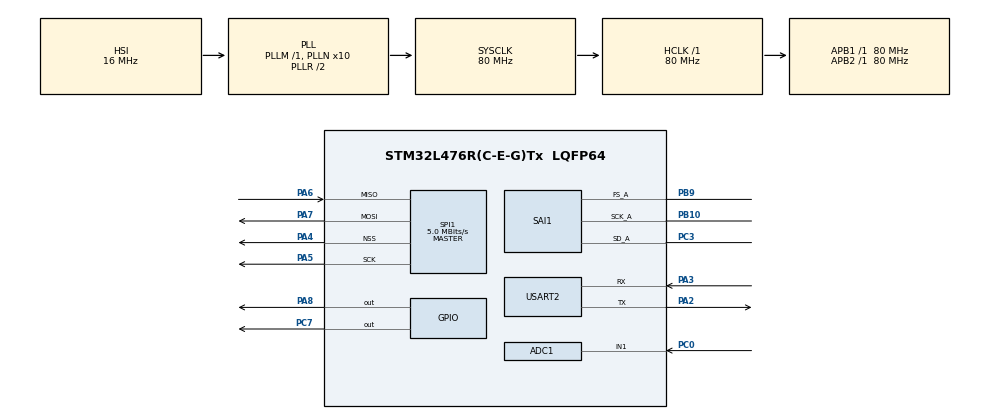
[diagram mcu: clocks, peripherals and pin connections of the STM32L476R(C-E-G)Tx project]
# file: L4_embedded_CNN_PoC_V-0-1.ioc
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ADC1.Channel-3\#ChannelRegularConversion=ADC_CHANNEL_1
ADC1.ClockPrescaler=ADC_CLOCK_ASYNC_DIV16
ADC1.NbrOfConversionFlag=1
ADC1.OffsetNumber-3\#ChannelRegularConversion=ADC_OFFSET_NONE
ADC1.Rank-3\#ChannelRegularConversion=1
ADC1.SamplingTime-3\#ChannelRegularConversion=ADC_SAMPLETIME_2CYCLES_5
ADC1.master=1
Dma.Request0=SAI1_A
Dma.SAI1_A.0.Direction=DMA_PERIPH_TO_MEMORY
Dma.SAI1_A.0.Instance=DMA2_Channel1
Dma.SAI1_A.0.MemDataAlignment=DMA_MDATAALIGN_WORD
Dma.SAI1_A.0.MemInc=DMA_MINC_ENABLE
Dma.SAI1_A.0.Mode=DMA_CIRCULAR
Dma.SAI1_A.0.PeriphDataAlignment=DMA_PDATAALIGN_WORD
Dma.SAI1_A.0.PeriphInc=DMA_PINC_DISABLE
Dma.SAI1_A.0.Priority=DMA_PRIORITY_HIGH
FREERTOS.Events01=hI2s_Evt,Dynamic,NULL
FREERTOS.Tasks01=defaultTask,24,128,StartDefaultTask,Default,NULL,Dynamic,NULL,NULL
FREERTOS.configUSE_NEWLIB_REENTRANT=1
Mcu.Family=STM32L4
Mcu.Name=STM32L476R(C-E-G)Tx
Mcu.Package=LQFP64
NVIC.DMA2_Channel1_IRQn=true\:5\:0\:false\:false\:true\:true\:false\:true
NVIC.PriorityGroup=NVIC_PRIORITYGROUP_4
NVIC.TIM1_TRG_COM_TIM17_IRQn=true\:15\:0\:false\:false\:true\:false\:false\:true
NVIC.TimeBase=TIM1_TRG_COM_TIM17_IRQn
NVIC.TimeBaseIP=TIM17
NVIC.USART2_IRQn=true\:5\:0\:false\:false\:true\:true\:true\:true
PA2.Mode=Asynchronous
PA2.Signal=USART2_TX
PA3.Mode=Asynchronous
PA3.Signal=USART2_RX
PA4.Mode=NSS_Signal_Hard_Output
PA4.Signal=SPI1_NSS
PA5.Mode=Full_Duplex_Master
PA5.Signal=SPI1_SCK
PA6.Mode=Full_Duplex_Master
PA6.Signal=SPI1_MISO
PA7.Mode=Full_Duplex_Master
PA7.Signal=SPI1_MOSI
PA8.GPIO_Speed=GPIO_SPEED_FREQ_HIGH
PA8.Signal=GPIO_Output
PB10.Mode=SAI_A_Master
PB10.Signal=SAI1_SCK_A
PB9.Mode=SAI_A_Master
PB9.Signal=SAI1_FS_A
PC0.Signal=ADCx_IN1
PC3.Mode=SAI_A_Master
PC3.Signal=SAI1_SD_A
PC7.GPIO_Speed=GPIO_SPEED_FREQ_HIGH
PC7.Signal=GPIO_Output
ProjectManager.HeapSize=0x800
ProjectManager.StackSize=0x800
ProjectManager.TargetToolchain=STM32CubeIDE
RCC.ADCFreq_Value=64000000
RCC.AHBFreq_Value=80000000
RCC.APB1Freq_Value=80000000
RCC.APB1TimFreq_Value=80000000
RCC.APB2Freq_Value=80000000
RCC.APB2TimFreq_Value=80000000
RCC.CortexFreq_Value=80000000
RCC.HCLKFreq_Value=80000000
RCC.HSE_VALUE=8000000
RCC.HSI_VALUE=16000000
RCC.LSE_VALUE=32768
RCC.MSI_VALUE=4000000
RCC.PLLN=10
RCC.PLLSourceVirtual=RCC_PLLSOURCE_HSI
RCC.PREFETCH_ENABLE=1
RCC.SYSCLKFreq_VALUE=80000000
RCC.SYSCLKSource=RCC_SYSCLKSOURCE_PLLCLK
RCC.USBFreq_Value=64000000
RCC.VCOOutputFreq_Value=160000000
SAI1.AudioFrequency-SAI_A_Master=SAI_AUDIO_FREQUENCY_48K
SAI1.AudioMode-SAI_A_Master=SAI_MODEMASTER_RX
SAI1.BasicDataSize-SAI_A_Master=SAI_PROTOCOL_DATASIZE_24BIT
SAI1.BasicProtocol-SAI_A_Master=SAI_I2S_STANDARD
SAI1.CompandingMode-SAI_A_Master=SAI_NOCOMPANDING
SAI1.ErrorAudioFreq-SAI_A_Master=48.8 %
SAI1.InitProtocol-SAI_A_Master=Enable
SAI1.Instance-SAI_A_Master=SAI$Index_Block_A
SAI1.MClockEnable-SAI_A_Master=SAI_MASTERCLOCK_DISABLE
SAI1.MonoStereoMode-SAI_A_Master=SAI_MONOMODE
SAI1.RealAudioFreq-SAI_A_Master=71.428 KHz
SAI1.VirtualMode-SAI_A_Master=VM_MASTER
SAI1.VirtualProtocol-SAI_A_BASIC=VM_BASIC_PROTOCOL
SH.ADCx_IN1.0=ADC1_IN1,IN1-Single-Ended
SPI1.BaudRatePrescaler=SPI_BAUDRATEPRESCALER_16
SPI1.CalculateBaudRate=5.0 MBits/s
SPI1.DataSize=SPI_DATASIZE_8BIT
SPI1.Direction=SPI_DIRECTION_2LINES
SPI1.Mode=SPI_MODE_MASTER
SPI1.VirtualNSS=VM_NSSHARD
SPI1.VirtualType=VM_MASTER
STMicroelectronics.X-CUBE-AI.7.1.0.ActivationBufferSizeList=46300
STMicroelectronics.X-CUBE-AI.7.1.0.ActivationBuffers=pool0
STMicroelectronics.X-CUBE-AI.7.1.0.ActivationNames=pool0
STMicroelectronics.X-CUBE-AI.7.1.0.ActivationSizes=AI_NETWORK_DATA_ACTIVATION_1_SIZE
STMicroelectronics.X-CUBE-AI.7.1.0.HeapSize=0x800
STMicroelectronics.X-CUBE-AI.7.1.0.InternalRamActivationBufferMaxSize=AI_NETWORK_DATA_ACTIVATIONS_SIZE
STMicroelectronics.X-CUBE-AI.7.1.0.LatestDirectoryUsed-8756bf45d95c8d5ad4c280e6ead7ad80c2c09bfcceebf7f6c182002fefabbdc1=C\:\\Users\\j.tschavoll\\OneDrive - FH Vorarlberg\\Partnerunternehmen FHV\\FH\\BA\\Code\\Jupyter\\N4CED_V-0-2
STMicroelectronics.X-CUBE-AI.7.1.0.MaximumNumberOfInputLayer=1
STMicroelectronics.X-CUBE-AI.7.1.0.MaximumNumberOfOutputLayer=1
STMicroelectronics.X-CUBE-AI.7.1.0.MaximumSizeOfInputLayer=AI_NETWORK_IN_1_SIZE_BYTES
STMicroelectronics.X-CUBE-AI.7.1.0.MaximumSizeOfOutputLayer=AI_NETWORK_OUT_1_SIZE_BYTES
STMicroelectronics.X-CUBE-AI.7.1.0.ModelActualCompression-8756bf45d95c8d5ad4c280e6ead7ad80c2c09bfcceebf7f6c182002fefabbdc1=2.67
STMicroelectronics.X-CUBE-AI.7.1.0.ModelCompression-8756bf45d95c8d5ad4c280e6ead7ad80c2c09bfcceebf7f6c182002fefabbdc1=4
STMicroelectronics.X-CUBE-AI.7.1.0.ModelFlashOccupation-8756bf45d95c8d5ad4c280e6ead7ad80c2c09bfcceebf7f6c182002fefabbdc1=282460
STMicroelectronics.X-CUBE-AI.7.1.0.ModelHashList=8756bf45d95c8d5ad4c280e6ead7ad80c2c09bfcceebf7f6c182002fefabbdc1
STMicroelectronics.X-CUBE-AI.7.1.0.ModelKind-8756bf45d95c8d5ad4c280e6ead7ad80c2c09bfcceebf7f6c182002fefabbdc1=TFLITE
STMicroelectronics.X-CUBE-AI.7.1.0.ModelMacc-8756bf45d95c8d5ad4c280e6ead7ad80c2c09bfcceebf7f6c182002fefabbdc1=5028040
STMicroelectronics.X-CUBE-AI.7.1.0.ModelName-8756bf45d95c8d5ad4c280e6ead7ad80c2c09bfcceebf7f6c182002fefabbdc1=network
STMicroelectronics.X-CUBE-AI.7.1.0.ModelNameList=network
STMicroelectronics.X-CUBE-AI.7.1.0.ModelRamOccupation-8756bf45d95c8d5ad4c280e6ead7ad80c2c09bfcceebf7f6c182002fefabbdc1=46300
STMicroelectronics.X-CUBE-AI.7.1.0.ModelStructureFile-8756bf45d95c8d5ad4c280e6ead7ad80c2c09bfcceebf7f6c182002fefabbdc1=C\:\\Users\\j.tschavoll\\OneDrive - FH Vorarlberg\\Partnerunternehmen FHV\\FH\\BA\\Code\\Jupyter\\N4CED_V-0-2\\N4CED_V-0-2_lite.tflite
STMicroelectronics.X-CUBE-AI.7.1.0.ModelType-8756bf45d95c8d5ad4c280e6ead7ad80c2c09bfcceebf7f6c182002fefabbdc1=STM32Cube.AI runtime
STMicroelectronics.X-CUBE-AI.7.1.0.ReadyForCodeGeneration=true
STMicroelectronics.X-CUBE-AI.7.1.0.StackSize=0x800
STMicroelectronics.X-CUBE-AI.7.1.0.WorkingBufferStartAddrList=0xFFFFFFFF
STMicroelectronics.X-CUBE-AI.7.1.0.XAaCUBEAaAICcArtificialOoIntelligenceJjCore=true
USART2.VirtualMode-Asynchronous=VM_ASYNC
VP_CRC_VS_CRC.Mode=CRC_Activate
VP_FATFS_VS_Generic.Mode=User_defined
VP_FREERTOS_VS_CMSIS_V2.Mode=CMSIS_V2
VP_SAI1_VP_$IpInstance_SAIA_SAI_BASIC.Mode=SAI_A_BASIC
VP_STMicroelectronics.X-CUBE-AI_VS_ArtificialOoIntelligenceJjXAaCUBEAaAI_7.1.0.Mode=ArtificialOoIntelligenceJjXAaCUBEAaAI
VP_SYS_VS_tim17.Mode=TIM17
board=NUCLEO-L476RG

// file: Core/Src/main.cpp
/* USER CODE BEGIN Header */
/**
  ******************************************************************************
  * @file           : main.c
  * @brief          : Main program body
  ******************************************************************************
  * @attention
  *
  * Copyright (c) 2022 STMicroelectronics.
  * All rights reserved.
  *
  * This software is licensed under terms that can be found in the LICENSE file
  * in the root directory of this software component.
  * If no LICENSE file comes with this software, it is provided AS-IS.
  *
  ******************************************************************************
  */
/* USER CODE END Header */
#include <entry.h>
#include "main.h"
#include "cmsis_os.h"
#include "fatfs.h"
#include "stm32l4xx_hal_cortex.h"

ADC_HandleTypeDef hadc1;

CRC_HandleTypeDef hcrc;

SAI_HandleTypeDef hsai_BlockA1;
DMA_HandleTypeDef hdma_sai1_a;

SPI_HandleTypeDef hspi1;

UART_HandleTypeDef huart2;

/* Definitions for defaultTask */
osThreadId_t defaultTaskHandle;
const osThreadAttr_t defaultTask_attributes = {
  .name = "defaultTask",
  .stack_size = 128 * 4,
  .priority = (osPriority_t) osPriorityHigh,
};

void SystemClock_Config(void);
void PeriphCommonClock_Config(void);
static void MX_GPIO_Init(void);
static void MX_DMA_Init(void);
static void MX_ADC1_Init(void);
static void MX_SAI1_Init(void);
static void MX_USART2_UART_Init(void);
static void MX_CRC_Init(void);
static void MX_SPI1_Init(void);
void StartDefaultTask(void *argument);

int main(void)
{

  /* MCU Configuration--------------------------------------------------------*/

  /* Reset of all peripherals, Initializes the Flash interface and the Systick. */
  HAL_Init();

  /* Configure the system clock */
  SystemClock_Config();

/* Configure the peripherals common clocks */
  PeriphCommonClock_Config();

  /* Initialize all configured peripherals */
  MX_GPIO_Init();
  MX_DMA_Init();
  MX_ADC1_Init();
  MX_SAI1_Init();
  MX_USART2_UART_Init();
  MX_CRC_Init();
  MX_SPI1_Init();
  MX_FATFS_Init();

  /* Init scheduler */
  osKernelInitialize();

  /* Create the thread(s) */
  /* creation of defaultTask */
  defaultTaskHandle = osThreadNew(StartDefaultTask, NULL, &defaultTask_attributes);

  /* Start scheduler */
  HAL_Delay(10);
  osKernelStart();

  /* We should never get here as control is now taken by the scheduler */
  /* Infinite loop */
  while (1)
  {

  }
}

void SystemClock_Config(void)
{
  RCC_OscInitTypeDef RCC_OscInitStruct = {0};
  RCC_ClkInitTypeDef RCC_ClkInitStruct = {0};

  /** Configure the main internal regulator output voltage
  */
  if (HAL_PWREx_ControlVoltageScaling(PWR_REGULATOR_VOLTAGE_SCALE1) != HAL_OK)
  {
    Error_Handler();
  }
  /** Initializes the RCC Oscillators according to the specified parameters
  * in the RCC_OscInitTypeDef structure.
  */
  RCC_OscInitStruct.OscillatorType = RCC_OSCILLATORTYPE_HSI;
  RCC_OscInitStruct.HSIState = RCC_HSI_ON;
  RCC_OscInitStruct.HSICalibrationValue = RCC_HSICALIBRATION_DEFAULT;
  RCC_OscInitStruct.PLL.PLLState = RCC_PLL_ON;
  RCC_OscInitStruct.PLL.PLLSource = RCC_PLLSOURCE_HSI;
  RCC_OscInitStruct.PLL.PLLM = 1;
  RCC_OscInitStruct.PLL.PLLN = 10;
  RCC_OscInitStruct.PLL.PLLP = RCC_PLLP_DIV7;
  RCC_OscInitStruct.PLL.PLLQ = RCC_PLLQ_DIV2;
  RCC_OscInitStruct.PLL.PLLR = RCC_PLLR_DIV2;
  if (HAL_RCC_OscConfig(&RCC_OscInitStruct) != HAL_OK)
  {
    Error_Handler();
  }
  /** Initializes the CPU, AHB and APB buses clocks
  */
  RCC_ClkInitStruct.ClockType = RCC_CLOCKTYPE_HCLK|RCC_CLOCKTYPE_SYSCLK
                              |RCC_CLOCKTYPE_PCLK1|RCC_CLOCKTYPE_PCLK2;
  RCC_ClkInitStruct.SYSCLKSource = RCC_SYSCLKSOURCE_PLLCLK;
  RCC_ClkInitStruct.AHBCLKDivider = RCC_SYSCLK_DIV1;
  RCC_ClkInitStruct.APB1CLKDivider = RCC_HCLK_DIV1;
  RCC_ClkInitStruct.APB2CLKDivider = RCC_HCLK_DIV1;

  if (HAL_RCC_ClockConfig(&RCC_ClkInitStruct, FLASH_LATENCY_4) != HAL_OK)
  {
    Error_Handler();
  }
}

void PeriphCommonClock_Config(void)
{
  RCC_PeriphCLKInitTypeDef PeriphClkInit = {0};

  /** Initializes the peripherals clock
  */
  PeriphClkInit.PeriphClockSelection = RCC_PERIPHCLK_SAI1|RCC_PERIPHCLK_ADC;
  PeriphClkInit.Sai1ClockSelection = RCC_SAI1CLKSOURCE_PLLSAI1;
  PeriphClkInit.AdcClockSelection = RCC_ADCCLKSOURCE_PLLSAI1;
  PeriphClkInit.PLLSAI1.PLLSAI1Source = RCC_PLLSOURCE_HSI;
  PeriphClkInit.PLLSAI1.PLLSAI1M = 1;
  PeriphClkInit.PLLSAI1.PLLSAI1N = 8;
  PeriphClkInit.PLLSAI1.PLLSAI1P = RCC_PLLP_DIV7;
  PeriphClkInit.PLLSAI1.PLLSAI1Q = RCC_PLLQ_DIV2;
  PeriphClkInit.PLLSAI1.PLLSAI1R = RCC_PLLR_DIV2;
  PeriphClkInit.PLLSAI1.PLLSAI1ClockOut = RCC_PLLSAI1_SAI1CLK|RCC_PLLSAI1_ADC1CLK;
  if (HAL_RCCEx_PeriphCLKConfig(&PeriphClkInit) != HAL_OK)
  {
    Error_Handler();
  }
}

static void MX_ADC1_Init(void)
{

  ADC_MultiModeTypeDef multimode = {0};
  ADC_ChannelConfTypeDef sConfig = {0};

  /** Common config
  */
  hadc1.Instance = ADC1;
  hadc1.Init.ClockPrescaler = ADC_CLOCK_ASYNC_DIV256;
  hadc1.Init.Resolution = ADC_RESOLUTION_12B;
  hadc1.Init.DataAlign = ADC_DATAALIGN_RIGHT;
  hadc1.Init.ScanConvMode = ADC_SCAN_DISABLE;
  hadc1.Init.EOCSelection = ADC_EOC_SINGLE_CONV;
  hadc1.Init.LowPowerAutoWait = DISABLE;
  hadc1.Init.ContinuousConvMode = DISABLE;
  hadc1.Init.NbrOfConversion = 1;
  hadc1.Init.DiscontinuousConvMode = DISABLE;
  hadc1.Init.ExternalTrigConv = ADC_SOFTWARE_START;
  hadc1.Init.ExternalTrigConvEdge = ADC_EXTERNALTRIGCONVEDGE_NONE;
  hadc1.Init.DMAContinuousRequests = DISABLE;
  hadc1.Init.Overrun = ADC_OVR_DATA_PRESERVED;
  hadc1.Init.OversamplingMode = DISABLE;
  if (HAL_ADC_Init(&hadc1) != HAL_OK)
  {
    Error_Handler();
  }
  /** Configure the ADC multi-mode
  */
  multimode.Mode = ADC_MODE_INDEPENDENT;
  if (HAL_ADCEx_MultiModeConfigChannel(&hadc1, &multimode) != HAL_OK)
  {
    Error_Handler();
  }
  /** Configure Regular Channel
  */
  sConfig.Channel = ADC_CHANNEL_1;
  sConfig.Rank = ADC_REGULAR_RANK_1;
  sConfig.SamplingTime = ADC_SAMPLETIME_2CYCLES_5;
  sConfig.SingleDiff = ADC_SINGLE_ENDED;
  sConfig.OffsetNumber = ADC_OFFSET_NONE;
  sConfig.Offset = 0;
  if (HAL_ADC_ConfigChannel(&hadc1, &sConfig) != HAL_OK)
  {
    Error_Handler();
  }

}

static void MX_CRC_Init(void)
{

  hcrc.Instance = CRC;
  hcrc.Init.DefaultPolynomialUse = DEFAULT_POLYNOMIAL_ENABLE;
  hcrc.Init.DefaultInitValueUse = DEFAULT_INIT_VALUE_ENABLE;
  hcrc.Init.InputDataInversionMode = CRC_INPUTDATA_INVERSION_NONE;
  hcrc.Init.OutputDataInversionMode = CRC_OUTPUTDATA_INVERSION_DISABLE;
  hcrc.InputDataFormat = CRC_INPUTDATA_FORMAT_BYTES;
  if (HAL_CRC_Init(&hcrc) != HAL_OK)
  {
    Error_Handler();
  }

}

static void MX_SAI1_Init(void)
{

  hsai_BlockA1.Instance = SAI1_Block_A;
  hsai_BlockA1.Init.AudioMode = SAI_MODEMASTER_RX;
  hsai_BlockA1.Init.Synchro = SAI_ASYNCHRONOUS;
  hsai_BlockA1.Init.OutputDrive = SAI_OUTPUTDRIVE_DISABLE;
  hsai_BlockA1.Init.NoDivider = SAI_MASTERDIVIDER_ENABLE;
  hsai_BlockA1.Init.FIFOThreshold = SAI_FIFOTHRESHOLD_EMPTY;
  hsai_BlockA1.Init.AudioFrequency = SAI_AUDIO_FREQUENCY_48K;
  hsai_BlockA1.Init.SynchroExt = SAI_SYNCEXT_DISABLE;
  hsai_BlockA1.Init.MonoStereoMode = SAI_MONOMODE;
  hsai_BlockA1.Init.CompandingMode = SAI_NOCOMPANDING;
  if (HAL_SAI_InitProtocol(&hsai_BlockA1, SAI_I2S_STANDARD, SAI_PROTOCOL_DATASIZE_24BIT, 2) != HAL_OK)
  {
    Error_Handler();
  }

}

static void MX_SPI1_Init(void)
{

  /* SPI1 parameter configuration*/
  hspi1.Instance = SPI1;
  hspi1.Init.Mode = SPI_MODE_MASTER;
  hspi1.Init.Direction = SPI_DIRECTION_2LINES;
  hspi1.Init.DataSize = SPI_DATASIZE_8BIT;
  hspi1.Init.CLKPolarity = SPI_POLARITY_LOW;
  hspi1.Init.CLKPhase = SPI_PHASE_1EDGE;
  hspi1.Init.NSS = SPI_NSS_HARD_OUTPUT;
  hspi1.Init.BaudRatePrescaler = SPI_BAUDRATEPRESCALER_16;
  hspi1.Init.FirstBit = SPI_FIRSTBIT_MSB;
  hspi1.Init.TIMode = SPI_TIMODE_DISABLE;
  hspi1.Init.CRCCalculation = SPI_CRCCALCULATION_DISABLE;
  hspi1.Init.CRCPolynomial = 7;
  hspi1.Init.CRCLength = SPI_CRC_LENGTH_DATASIZE;
  hspi1.Init.NSSPMode = SPI_NSS_PULSE_ENABLE;
  if (HAL_SPI_Init(&hspi1) != HAL_OK)
  {
    Error_Handler();
  }

}

static void MX_USART2_UART_Init(void)
{

  huart2.Instance = USART2;
  huart2.Init.BaudRate = 115200;
  huart2.Init.WordLength = UART_WORDLENGTH_8B;
  huart2.Init.StopBits = UART_STOPBITS_1;
  huart2.Init.Parity = UART_PARITY_NONE;
  huart2.Init.Mode = UART_MODE_TX_RX;
  huart2.Init.HwFlowCtl = UART_HWCONTROL_NONE;
  huart2.Init.OverSampling = UART_OVERSAMPLING_16;
  huart2.Init.OneBitSampling = UART_ONE_BIT_SAMPLE_DISABLE;
  huart2.AdvancedInit.AdvFeatureInit = UART_ADVFEATURE_NO_INIT;
  if (HAL_UART_Init(&huart2) != HAL_OK)
  {
    Error_Handler();
  }

}

static void MX_DMA_Init(void)
{

  /* DMA controller clock enable */
  __HAL_RCC_DMA2_CLK_ENABLE();

  /* DMA interrupt init */
  /* DMA2_Channel1_IRQn interrupt configuration */
  HAL_NVIC_SetPriority(DMA2_Channel1_IRQn, 5, 0);
  HAL_NVIC_EnableIRQ(DMA2_Channel1_IRQn);

}

static void MX_GPIO_Init(void)
{
  GPIO_InitTypeDef GPIO_InitStruct = {0};

  /* GPIO Ports Clock Enable */
  __HAL_RCC_GPIOC_CLK_ENABLE();
  __HAL_RCC_GPIOA_CLK_ENABLE();
  __HAL_RCC_GPIOB_CLK_ENABLE();

  /*Configure GPIO pin Output Level */
  HAL_GPIO_WritePin(GPIOC, GPIO_PIN_7, GPIO_PIN_RESET);

  /*Configure GPIO pin Output Level */
  HAL_GPIO_WritePin(GPIOA, GPIO_PIN_8, GPIO_PIN_RESET);

  /*Configure GPIO pin : PC7 */
  GPIO_InitStruct.Pin = GPIO_PIN_7;
  GPIO_InitStruct.Mode = GPIO_MODE_OUTPUT_PP;
  GPIO_InitStruct.Pull = GPIO_NOPULL;
  GPIO_InitStruct.Speed = GPIO_SPEED_FREQ_HIGH;
  HAL_GPIO_Init(GPIOC, &GPIO_InitStruct);

  /*Configure GPIO pin : PA8 */
  GPIO_InitStruct.Pin = GPIO_PIN_8;
  GPIO_InitStruct.Mode = GPIO_MODE_OUTPUT_PP;
  GPIO_InitStruct.Pull = GPIO_NOPULL;
  GPIO_InitStruct.Speed = GPIO_SPEED_FREQ_HIGH;
  HAL_GPIO_Init(GPIOA, &GPIO_InitStruct);

}

void StartDefaultTask(void *argument)
{
  /* USER CODE BEGIN 5 */
	entry();
	osThreadSetPriority(defaultTaskHandle, osPriorityBelowNormal);
	osThreadTerminate(defaultTaskHandle);
	while(1);
  /* USER CODE END 5 */
}

void HAL_TIM_PeriodElapsedCallback(TIM_HandleTypeDef *htim)
{
  if (htim->Instance == TIM17) {
    HAL_IncTick();
  }
}

void Error_Handler(void)
{
  __disable_irq();
  while (1)
  {
  }
}
